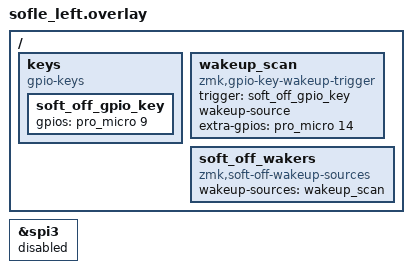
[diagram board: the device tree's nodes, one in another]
/*
 * No LEDs are fitted. The Sofle shield puts the WS2812 data line on spi3 MOSI (P0.06),
 * which is also the nice!view chip select (pro_micro 1), so turn the LED SPI bus off.
 */
&spi3 {
    status = "disabled";
};

/*
 * Wake from soft off with the Lower key: row 4 (pro_micro 9) / col 3 (pro_micro 14).
 * The column is driven high before powering off and the row pin wakes the chip.
 */
/ {
    keys {
        compatible = "gpio-keys";
        soft_off_gpio_key: soft_off_gpio_key {
            gpios = <&pro_micro 9 (GPIO_ACTIVE_HIGH | GPIO_PULL_DOWN)>;
        };
    };

    wakeup_scan: wakeup_scan {
        compatible = "zmk,gpio-key-wakeup-trigger";
        trigger = <&soft_off_gpio_key>;
        wakeup-source;
        extra-gpios = <&pro_micro 14 GPIO_ACTIVE_HIGH>;
    };

    soft_off_wakers {
        compatible = "zmk,soft-off-wakeup-sources";
        wakeup-sources = <&wakeup_scan>;
    };
};
